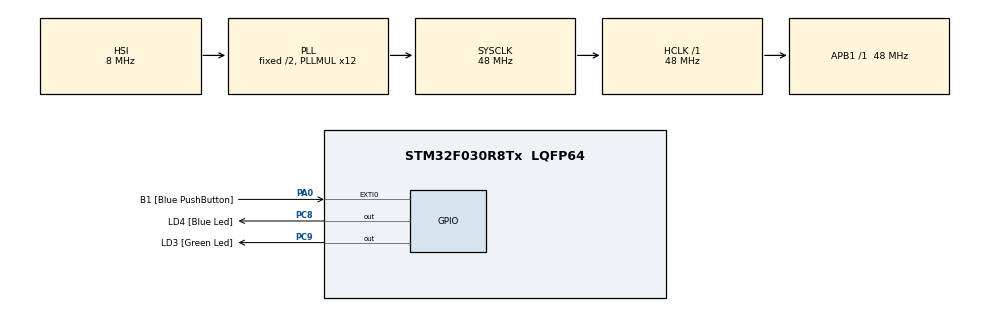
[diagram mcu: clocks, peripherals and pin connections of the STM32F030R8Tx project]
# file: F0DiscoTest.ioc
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Mcu.Family=STM32F0
Mcu.Name=STM32F030R8Tx
Mcu.Package=LQFP64
PA0.GPIO_Label=B1 [Blue PushButton]
PA0.GPIO_ModeDefaultEXTI=GPIO_MODE_EVT_RISING
PA0.Signal=GPXTI0
PA13.GPIO_Label=SWDIO
PA13.Mode=Serial_Wire
PA13.Signal=SYS_SWDIO
PA14.GPIO_Label=SWCLK
PA14.Mode=Serial_Wire
PA14.Signal=SYS_SWCLK
PC8.GPIO_Label=LD4 [Blue Led]
PC8.Signal=GPIO_Output
PC9.GPIO_Label=LD3 [Green Led]
PC9.Signal=GPIO_Output
ProjectManager.HeapSize=0x200
ProjectManager.StackSize=0x400
ProjectManager.TargetToolchain=SW4STM32
RCC.AHBFreq_Value=48000000
RCC.APB1Freq_Value=48000000
RCC.APB1TimFreq_Value=48000000
RCC.HCLKFreq_Value=48000000
RCC.PLLMUL=RCC_PLL_MUL12
RCC.SYSCLKFreq_VALUE=48000000
RCC.SYSCLKSource=RCC_SYSCLKSOURCE_PLLCLK
board=STM32F0308-DISCO

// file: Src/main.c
/* USER CODE BEGIN Header */
/**
  ******************************************************************************
  * @file           : main.c
  * @brief          : Main program body
  ******************************************************************************
  * @attention
  *
  * <h2><center>&copy; Copyright (c) 2020 STMicroelectronics.
  * All rights reserved.</center></h2>
  *
  * This software component is licensed by ST under BSD 3-Clause license,
  * the "License"; You may not use this file except in compliance with the
  * License. You may obtain a copy of the License at:
  *                        opensource.org/licenses/BSD-3-Clause
  *
  ******************************************************************************
  */
/* USER CODE END Header */

#include "main.h"

void SystemClock_Config(void);
static void MX_GPIO_Init(void);

/* USER CODE BEGIN 0 */
volatile uint8_t counter = 0;
/* USER CODE END 0 */

inline void toggle_led3(void){
  HAL_GPIO_TogglePin(LD3_GPIO_Port, LD3_Pin);
}

int main(void)
{

  /* MCU Configuration--------------------------------------------------------*/

  /* Reset of all peripherals, Initializes the Flash interface and the Systick. */
  HAL_Init();

  /* Configure the system clock */
  SystemClock_Config();

  /* Initialize all configured peripherals */
  MX_GPIO_Init();

  /* Infinite loop */
  while (1)
  {

    /* USER CODE BEGIN 3 */
    counter++;

    #ifdef HELLO_THERE
    HAL_GPIO_WritePin(LD4_GPIO_Port,LD4_Pin, 0);
    #endif

    #ifdef GENERAL_KENOBI
    HAL_GPIO_TogglePin(LD4_GPIO_Port,LD4_Pin);
    #endif

    toggle_led3();
    HAL_Delay(100);
  }
  /* USER CODE END 3 */
}

void SystemClock_Config(void)
{
  RCC_OscInitTypeDef RCC_OscInitStruct = {0};
  RCC_ClkInitTypeDef RCC_ClkInitStruct = {0};

  /** Initializes the CPU, AHB and APB busses clocks
  */
  RCC_OscInitStruct.OscillatorType = RCC_OSCILLATORTYPE_HSI;
  RCC_OscInitStruct.HSIState = RCC_HSI_ON;
  RCC_OscInitStruct.HSICalibrationValue = RCC_HSICALIBRATION_DEFAULT;
  RCC_OscInitStruct.PLL.PLLState = RCC_PLL_ON;
  RCC_OscInitStruct.PLL.PLLSource = RCC_PLLSOURCE_HSI;
  RCC_OscInitStruct.PLL.PLLMUL = RCC_PLL_MUL12;
  RCC_OscInitStruct.PLL.PREDIV = RCC_PREDIV_DIV1;
  if (HAL_RCC_OscConfig(&RCC_OscInitStruct) != HAL_OK)
  {
    Error_Handler();
  }
  /** Initializes the CPU, AHB and APB busses clocks
  */
  RCC_ClkInitStruct.ClockType = RCC_CLOCKTYPE_HCLK|RCC_CLOCKTYPE_SYSCLK
                              |RCC_CLOCKTYPE_PCLK1;
  RCC_ClkInitStruct.SYSCLKSource = RCC_SYSCLKSOURCE_PLLCLK;
  RCC_ClkInitStruct.AHBCLKDivider = RCC_SYSCLK_DIV1;
  RCC_ClkInitStruct.APB1CLKDivider = RCC_HCLK_DIV1;

  if (HAL_RCC_ClockConfig(&RCC_ClkInitStruct, FLASH_LATENCY_1) != HAL_OK)
  {
    Error_Handler();
  }
}

static void MX_GPIO_Init(void)
{
  GPIO_InitTypeDef GPIO_InitStruct = {0};

  /* GPIO Ports Clock Enable */
  __HAL_RCC_GPIOA_CLK_ENABLE();
  __HAL_RCC_GPIOC_CLK_ENABLE();

  /*Configure GPIO pin Output Level */
  HAL_GPIO_WritePin(GPIOC, LD4_Pin|LD3_Pin, GPIO_PIN_RESET);

  /*Configure GPIO pin : B1_Pin */
  GPIO_InitStruct.Pin = B1_Pin;
  GPIO_InitStruct.Mode = GPIO_MODE_EVT_RISING;
  GPIO_InitStruct.Pull = GPIO_NOPULL;
  HAL_GPIO_Init(B1_GPIO_Port, &GPIO_InitStruct);

  /*Configure GPIO pins : LD4_Pin LD3_Pin */
  GPIO_InitStruct.Pin = LD4_Pin|LD3_Pin;
  GPIO_InitStruct.Mode = GPIO_MODE_OUTPUT_PP;
  GPIO_InitStruct.Pull = GPIO_NOPULL;
  GPIO_InitStruct.Speed = GPIO_SPEED_FREQ_LOW;
  HAL_GPIO_Init(GPIOC, &GPIO_InitStruct);

}

void Error_Handler(void)
{
}

/************************ (C) COPYRIGHT STMicroelectronics *****END OF FILE****/
